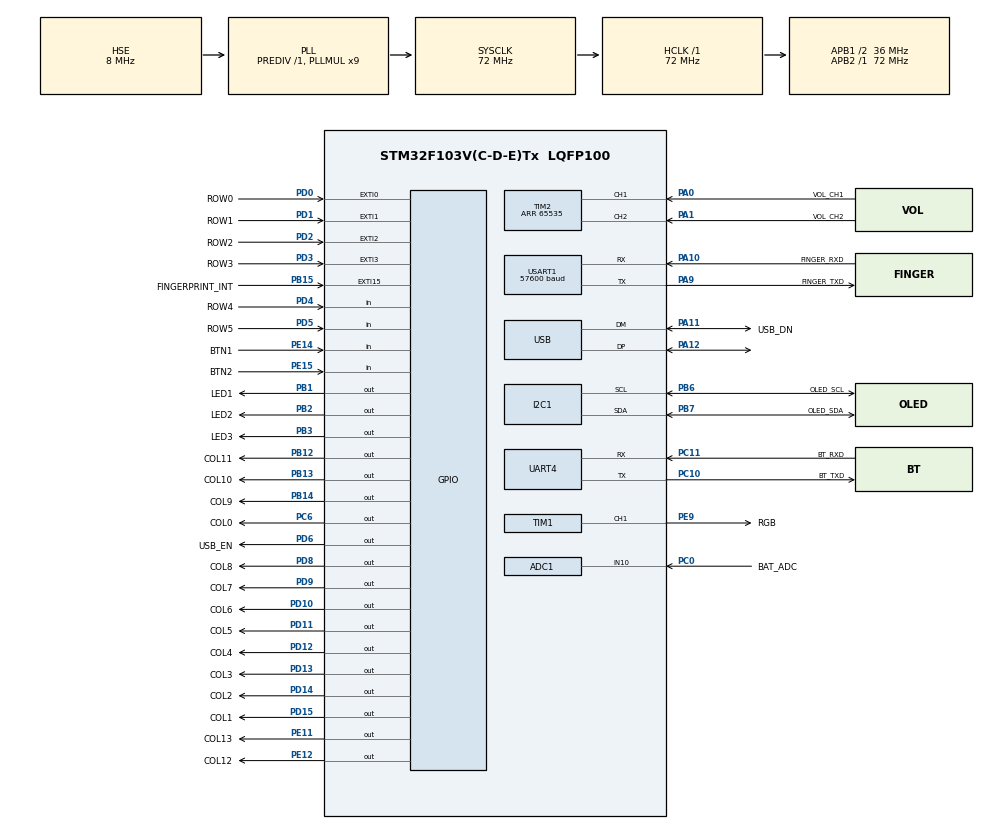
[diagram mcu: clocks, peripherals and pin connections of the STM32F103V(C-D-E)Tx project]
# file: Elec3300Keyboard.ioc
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ADC1.Channel-0\#ChannelRegularConversion=ADC_CHANNEL_10
ADC1.ContinuousConvMode=ENABLE
ADC1.NbrOfConversionFlag=1
ADC1.Rank-0\#ChannelRegularConversion=1
ADC1.SamplingTime-0\#ChannelRegularConversion=ADC_SAMPLETIME_1CYCLE_5
ADC1.master=1
Dma.Request0=TIM1_CH1
Dma.TIM1_CH1.0.Direction=DMA_MEMORY_TO_PERIPH
Dma.TIM1_CH1.0.Instance=DMA1_Channel2
Dma.TIM1_CH1.0.MemDataAlignment=DMA_MDATAALIGN_WORD
Dma.TIM1_CH1.0.MemInc=DMA_MINC_ENABLE
Dma.TIM1_CH1.0.Mode=DMA_NORMAL
Dma.TIM1_CH1.0.PeriphDataAlignment=DMA_PDATAALIGN_HALFWORD
Dma.TIM1_CH1.0.PeriphInc=DMA_PINC_DISABLE
Dma.TIM1_CH1.0.Priority=DMA_PRIORITY_LOW
FREERTOS.HEAP_NUMBER=3
FREERTOS.Tasks01=KeyTask,3,128,StartUSBTask,Default,NULL,Dynamic,NULL,NULL;OLEDTask,-3,128,StartOLEDTask,Default,NULL,Dynamic,NULL,NULL;RGBTask,-3,128,WS2812_LED_Task,Default,NULL,Dynamic,NULL,NULL;debugTask,-3,128,StartDebugTask,Default,NULL,Dynamic,NULL,NULL
Mcu.Family=STM32F1
Mcu.Name=STM32F103V(C-D-E)Tx
Mcu.Package=LQFP100
NVIC.DMA1_Channel2_IRQn=true\:5\:0\:false\:false\:true\:true\:false\:true
NVIC.EXTI0_IRQn=true\:5\:0\:false\:false\:true\:true\:true\:true
NVIC.EXTI15_10_IRQn=true\:5\:0\:false\:false\:true\:true\:true\:true
NVIC.EXTI1_IRQn=true\:5\:0\:false\:false\:true\:true\:true\:true
NVIC.EXTI2_IRQn=true\:5\:0\:false\:false\:true\:true\:true\:true
NVIC.EXTI3_IRQn=true\:5\:0\:false\:false\:true\:true\:true\:true
NVIC.PriorityGroup=NVIC_PRIORITYGROUP_4
NVIC.TIM2_IRQn=true\:5\:0\:false\:false\:true\:true\:true\:true
NVIC.TIM6_IRQn=true\:0\:0\:false\:false\:true\:false\:false\:true
NVIC.TimeBase=TIM6_IRQn
NVIC.TimeBaseIP=TIM6
NVIC.USB_LP_CAN1_RX0_IRQn=true\:5\:0\:false\:false\:true\:true\:false\:true
OSC_IN.Mode=HSE-External-Oscillator
OSC_IN.Signal=RCC_OSC_IN
OSC_OUT.Mode=HSE-External-Oscillator
OSC_OUT.Signal=RCC_OSC_OUT
PA0-WKUP.GPIO_Label=VOL_CH1
PA0-WKUP.GPIO_PuPd=GPIO_PULLUP
PA0-WKUP.Signal=S_TIM2_CH1_ETR
PA1.GPIO_Label=VOL_CH2
PA1.GPIO_PuPd=GPIO_PULLUP
PA1.Signal=S_TIM2_CH2
PA10.GPIO_Label=FINGER_RXD
PA10.Mode=Asynchronous
PA10.Signal=USART1_RX
PA11.GPIO_Label=USB_DN
PA11.Mode=Device
PA11.Signal=USB_DM
PA12.Mode=Device
PA12.Signal=USB_DP
PA13.Mode=Serial_Wire
PA13.Signal=SYS_JTMS-SWDIO
PA14.Mode=Serial_Wire
PA14.Signal=SYS_JTCK-SWCLK
PA9.GPIO_Label=FINGER_TXD
PA9.Mode=Asynchronous
PA9.Signal=USART1_TX
PB1.GPIO_Label=LED1
PB1.Signal=GPIO_Output
PB12.GPIO_Label=COL11
PB12.Signal=GPIO_Output
PB13.GPIO_Label=COL10
PB13.Signal=GPIO_Output
PB14.GPIO_Label=COL9
PB14.Signal=GPIO_Output
PB15.GPIO_Label=FINGERPRINT_INT
PB15.GPIO_PuPd=GPIO_PULLDOWN
PB15.Signal=GPXTI15
PB2.GPIO_Label=LED2
PB2.Signal=GPIO_Output
PB3.GPIO_Label=LED3
PB3.Signal=GPIO_Output
PB6.GPIO_Label=OLED_SCL
PB6.Mode=I2C
PB6.Signal=I2C1_SCL
PB7.GPIO_Label=OLED_SDA
PB7.Mode=I2C
PB7.Signal=I2C1_SDA
PC0.GPIO_Label=BAT_ADC
PC0.Signal=ADCx_IN10
PC10.GPIO_Label=BT_TXD
PC10.Mode=Asynchronous
PC10.Signal=UART4_TX
PC11.GPIO_Label=BT_RXD
PC11.Mode=Asynchronous
PC11.Signal=UART4_RX
PC14-OSC32_IN.Mode=LSE-External-Oscillator
PC14-OSC32_IN.Signal=RCC_OSC32_IN
PC15-OSC32_OUT.Mode=LSE-External-Oscillator
PC15-OSC32_OUT.Signal=RCC_OSC32_OUT
PC6.GPIO_Label=COL0
PC6.Signal=GPIO_Output
PD0.GPIO_Label=ROW0
PD0.GPIO_PuPd=GPIO_PULLDOWN
PD0.Signal=GPXTI0
PD1.GPIO_Label=ROW1
PD1.GPIO_PuPd=GPIO_PULLDOWN
PD1.Signal=GPXTI1
PD10.GPIO_Label=COL6
PD10.Signal=GPIO_Output
PD11.GPIO_Label=COL5
PD11.Signal=GPIO_Output
PD12.GPIO_Label=COL4
PD12.Signal=GPIO_Output
PD13.GPIO_Label=COL3
PD13.Signal=GPIO_Output
PD14.GPIO_Label=COL2
PD14.Signal=GPIO_Output
PD15.GPIO_Label=COL1
PD15.Signal=GPIO_Output
PD2.GPIO_Label=ROW2
PD2.GPIO_PuPd=GPIO_PULLDOWN
PD2.Signal=GPXTI2
PD3.GPIO_Label=ROW3
PD3.GPIO_PuPd=GPIO_PULLDOWN
PD3.Signal=GPXTI3
PD4.GPIO_Label=ROW4
PD4.GPIO_PuPd=GPIO_PULLDOWN
PD4.Signal=GPIO_Input
PD5.GPIO_Label=ROW5
PD5.GPIO_PuPd=GPIO_PULLDOWN
PD5.Signal=GPIO_Input
PD6.GPIO_Label=USB_EN
PD6.Signal=GPIO_Output
PD8.GPIO_Label=COL8
PD8.Signal=GPIO_Output
PD9.GPIO_Label=COL7
PD9.Signal=GPIO_Output
PE11.GPIO_Label=COL13
PE11.Signal=GPIO_Output
PE12.GPIO_Label=COL12
PE12.Signal=GPIO_Output
PE14.GPIO_Label=BTN1
PE14.GPIO_PuPd=GPIO_PULLDOWN
PE14.Signal=GPIO_Input
PE15.GPIO_Label=BTN2
PE15.GPIO_PuPd=GPIO_PULLDOWN
PE15.Signal=GPIO_Input
PE9.GPIO_Label=RGB
PE9.Signal=S_TIM1_CH1
ProjectManager.HeapSize=0x200
ProjectManager.StackSize=0x400
ProjectManager.TargetToolchain=Makefile
RCC.ADCPresc=RCC_ADCPCLK2_DIV6
RCC.AHBFreq_Value=72000000
RCC.APB1CLKDivider=RCC_HCLK_DIV2
RCC.APB1Freq_Value=36000000
RCC.APB1TimFreq_Value=72000000
RCC.APB2Freq_Value=72000000
RCC.APB2TimFreq_Value=72000000
RCC.HCLKFreq_Value=72000000
RCC.PLLMUL=RCC_PLL_MUL9
RCC.SYSCLKFreq_VALUE=72000000
RCC.SYSCLKSource=RCC_SYSCLKSOURCE_PLLCLK
RCC.USBFreq_Value=48000000
RCC.USBPrescaler=RCC_USBCLKSOURCE_PLL_DIV1_5
SH.ADCx_IN10.0=ADC1_IN10,IN10
SH.S_TIM1_CH1.0=TIM1_CH1,PWM Generation1 CH1
SH.S_TIM2_CH1_ETR.0=TIM2_CH1,Encoder_Interface
SH.S_TIM2_CH2.0=TIM2_CH2,Encoder_Interface
TIM1.Channel-PWM\ Generation1\ CH1=TIM_CHANNEL_1
TIM1.Channel-PWM\ Generation2\ CH2=TIM_CHANNEL_2
TIM1.Period=50-1
TIM1.Prescaler=2-1
TIM1.Pulse-PWM\ Generation1\ CH1=0
TIM2.AutoReloadPreload=TIM_AUTORELOAD_PRELOAD_DISABLE
TIM2.EncoderMode=TIM_ENCODERMODE_TI12
TIM2.IC1Polarity=TIM_ICPOLARITY_FALLING
TIM2.IC2Polarity=TIM_ICPOLARITY_FALLING
TIM2.Period=65535
UART4.VirtualMode=Asynchronous
USART1.BaudRate=57600
USART1.VirtualMode=VM_ASYNC
USB_DEVICE.CLASS_NAME_FS=HID
USB_DEVICE.PRODUCT_STRING_HID_FS=STM32keyboard
USB_DEVICE.VirtualMode=Hid
USB_DEVICE.VirtualModeFS=Hid_FS
VP_FREERTOS_VS_CMSIS_V1.Mode=CMSIS_V1
VP_SYS_VS_tim6.Mode=TIM6
VP_TIM1_VS_ClockSourceINT.Mode=Internal
VP_USB_DEVICE_VS_USB_DEVICE_HID_FS.Mode=HID_FS
board=custom

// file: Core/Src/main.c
/* USER CODE BEGIN Header */
/* USER CODE END Header */

#include "main.h"

#include "cmsis_os.h"
#include "usb_device.h"

/* USER CODE BEGIN Includes */
#include "RGB.h"
#include "battery.h"
#include "display_manager.h"
#include "fingerprint.h"
#include "host_OS.h"
#include "key_handler.h"
#include "matrix_button.h"
#include "oled_manager.h"
#include "ssd1306.h"
#include "volume.h"
/* USER CODE END Includes */

ADC_HandleTypeDef hadc1;

I2C_HandleTypeDef hi2c1;

TIM_HandleTypeDef htim1;
TIM_HandleTypeDef htim2;
DMA_HandleTypeDef hdma_tim1_ch1;

UART_HandleTypeDef huart4;
UART_HandleTypeDef huart1;

osThreadId KeyTaskHandle;
osThreadId OLEDTaskHandle;
osThreadId RGBTaskHandle;
osThreadId debugTaskHandle;
/* USER CODE BEGIN PV */
extern WS2812 ws2812;
/* USER CODE END PV */

void SystemClock_Config(void);
static void MX_GPIO_Init(void);
static void MX_ADC1_Init(void);
static void MX_TIM1_Init(void);
static void MX_I2C1_Init(void);
static void MX_DMA_Init(void);
static void MX_UART4_Init(void);
static void MX_TIM2_Init(void);
static void MX_USART1_UART_Init(void);
void StartUSBTask(void const *argument);
void StartOLEDTask(void const *argument);
void WS2812_LED_Task(void const *argument);
void StartDebugTask(void const *argument);

int main(void) {

    /* MCU Configuration--------------------------------------------------------*/

    /* Reset of all peripherals, Initializes the Flash interface and the Systick. */
    HAL_Init();

    /* Configure the system clock */
    SystemClock_Config();

    /* Initialize all configured peripherals */
    MX_GPIO_Init();
    MX_ADC1_Init();
    MX_DMA_Init();
    MX_TIM1_Init();
    MX_I2C1_Init();
    MX_UART4_Init();
    MX_TIM2_Init();
    MX_USART1_UART_Init();
    /* USER CODE BEGIN 2 */
    HAL_ADCEx_Calibration_Start(&hadc1);
    HAL_ADC_Start(&hadc1);
    HAL_TIM_Encoder_Start_IT(&htim2, TIM_CHANNEL_ALL);
    /* USER CODE END 2 */

    /* Create the thread(s) */
    /* definition and creation of KeyTask */
    osThreadDef(KeyTask, StartUSBTask, osPriorityRealtime, 0, 128);
    KeyTaskHandle = osThreadCreate(osThread(KeyTask), NULL);

    /* definition and creation of OLEDTask */
    osThreadDef(OLEDTask, StartOLEDTask, osPriorityIdle, 0, 128);
    OLEDTaskHandle = osThreadCreate(osThread(OLEDTask), NULL);

    /* definition and creation of RGBTask */
    osThreadDef(RGBTask, WS2812_LED_Task, osPriorityIdle, 0, 128);
    RGBTaskHandle = osThreadCreate(osThread(RGBTask), NULL);

    /* definition and creation of debugTask */
    osThreadDef(debugTask, StartDebugTask, osPriorityIdle, 0, 128);
    debugTaskHandle = osThreadCreate(osThread(debugTask), NULL);

    /* Start scheduler */
    osKernelStart();

    /* We should never get here as control is now taken by the scheduler */

    /* Infinite loop */

}

void SystemClock_Config(void) {
    RCC_OscInitTypeDef RCC_OscInitStruct = {0};
    RCC_ClkInitTypeDef RCC_ClkInitStruct = {0};
    RCC_PeriphCLKInitTypeDef PeriphClkInit = {0};

    /** Initializes the CPU, AHB and APB busses clocks
  */
    RCC_OscInitStruct.OscillatorType = RCC_OSCILLATORTYPE_HSE;
    RCC_OscInitStruct.HSEState = RCC_HSE_ON;
    RCC_OscInitStruct.HSEPredivValue = RCC_HSE_PREDIV_DIV1;
    RCC_OscInitStruct.HSIState = RCC_HSI_ON;
    RCC_OscInitStruct.PLL.PLLState = RCC_PLL_ON;
    RCC_OscInitStruct.PLL.PLLSource = RCC_PLLSOURCE_HSE;
    RCC_OscInitStruct.PLL.PLLMUL = RCC_PLL_MUL9;
    if (HAL_RCC_OscConfig(&RCC_OscInitStruct) != HAL_OK) {
        Error_Handler();
    }
    /** Initializes the CPU, AHB and APB busses clocks
  */
    RCC_ClkInitStruct.ClockType = RCC_CLOCKTYPE_HCLK | RCC_CLOCKTYPE_SYSCLK | RCC_CLOCKTYPE_PCLK1 | RCC_CLOCKTYPE_PCLK2;
    RCC_ClkInitStruct.SYSCLKSource = RCC_SYSCLKSOURCE_PLLCLK;
    RCC_ClkInitStruct.AHBCLKDivider = RCC_SYSCLK_DIV1;
    RCC_ClkInitStruct.APB1CLKDivider = RCC_HCLK_DIV2;
    RCC_ClkInitStruct.APB2CLKDivider = RCC_HCLK_DIV1;

    if (HAL_RCC_ClockConfig(&RCC_ClkInitStruct, FLASH_LATENCY_2) != HAL_OK) {
        Error_Handler();
    }
    PeriphClkInit.PeriphClockSelection = RCC_PERIPHCLK_ADC | RCC_PERIPHCLK_USB;
    PeriphClkInit.AdcClockSelection = RCC_ADCPCLK2_DIV6;
    PeriphClkInit.UsbClockSelection = RCC_USBCLKSOURCE_PLL_DIV1_5;
    if (HAL_RCCEx_PeriphCLKConfig(&PeriphClkInit) != HAL_OK) {
        Error_Handler();
    }
}

static void MX_ADC1_Init(void) {

    ADC_ChannelConfTypeDef sConfig = {0};

    /** Common config
  */
    hadc1.Instance = ADC1;
    hadc1.Init.ScanConvMode = ADC_SCAN_DISABLE;
    hadc1.Init.ContinuousConvMode = ENABLE;
    hadc1.Init.DiscontinuousConvMode = DISABLE;
    hadc1.Init.ExternalTrigConv = ADC_SOFTWARE_START;
    hadc1.Init.DataAlign = ADC_DATAALIGN_RIGHT;
    hadc1.Init.NbrOfConversion = 1;
    if (HAL_ADC_Init(&hadc1) != HAL_OK) {
        Error_Handler();
    }
    /** Configure Regular Channel
  */
    sConfig.Channel = ADC_CHANNEL_10;
    sConfig.Rank = ADC_REGULAR_RANK_1;
    sConfig.SamplingTime = ADC_SAMPLETIME_1CYCLE_5;
    if (HAL_ADC_ConfigChannel(&hadc1, &sConfig) != HAL_OK) {
        Error_Handler();
    }
}

static void MX_I2C1_Init(void) {

    hi2c1.Instance = I2C1;
    hi2c1.Init.ClockSpeed = 100000;
    hi2c1.Init.DutyCycle = I2C_DUTYCYCLE_2;
    hi2c1.Init.OwnAddress1 = 0;
    hi2c1.Init.AddressingMode = I2C_ADDRESSINGMODE_7BIT;
    hi2c1.Init.DualAddressMode = I2C_DUALADDRESS_DISABLE;
    hi2c1.Init.OwnAddress2 = 0;
    hi2c1.Init.GeneralCallMode = I2C_GENERALCALL_DISABLE;
    hi2c1.Init.NoStretchMode = I2C_NOSTRETCH_DISABLE;
    if (HAL_I2C_Init(&hi2c1) != HAL_OK) {
        Error_Handler();
    }
}

static void MX_TIM1_Init(void) {

    TIM_ClockConfigTypeDef sClockSourceConfig = {0};
    TIM_MasterConfigTypeDef sMasterConfig = {0};
    TIM_OC_InitTypeDef sConfigOC = {0};
    TIM_BreakDeadTimeConfigTypeDef sBreakDeadTimeConfig = {0};

    htim1.Instance = TIM1;
    htim1.Init.Prescaler = 2 - 1;
    htim1.Init.CounterMode = TIM_COUNTERMODE_UP;
    htim1.Init.Period = 50 - 1;
    htim1.Init.ClockDivision = TIM_CLOCKDIVISION_DIV1;
    htim1.Init.RepetitionCounter = 0;
    htim1.Init.AutoReloadPreload = TIM_AUTORELOAD_PRELOAD_DISABLE;
    if (HAL_TIM_Base_Init(&htim1) != HAL_OK) {
        Error_Handler();
    }
    sClockSourceConfig.ClockSource = TIM_CLOCKSOURCE_INTERNAL;
    if (HAL_TIM_ConfigClockSource(&htim1, &sClockSourceConfig) != HAL_OK) {
        Error_Handler();
    }
    if (HAL_TIM_PWM_Init(&htim1) != HAL_OK) {
        Error_Handler();
    }
    sMasterConfig.MasterOutputTrigger = TIM_TRGO_RESET;
    sMasterConfig.MasterSlaveMode = TIM_MASTERSLAVEMODE_DISABLE;
    if (HAL_TIMEx_MasterConfigSynchronization(&htim1, &sMasterConfig) != HAL_OK) {
        Error_Handler();
    }
    sConfigOC.OCMode = TIM_OCMODE_PWM1;
    sConfigOC.Pulse = 0;
    sConfigOC.OCPolarity = TIM_OCPOLARITY_HIGH;
    sConfigOC.OCNPolarity = TIM_OCNPOLARITY_HIGH;
    sConfigOC.OCFastMode = TIM_OCFAST_DISABLE;
    sConfigOC.OCIdleState = TIM_OCIDLESTATE_RESET;
    sConfigOC.OCNIdleState = TIM_OCNIDLESTATE_RESET;
    if (HAL_TIM_PWM_ConfigChannel(&htim1, &sConfigOC, TIM_CHANNEL_1) != HAL_OK) {
        Error_Handler();
    }
    sBreakDeadTimeConfig.OffStateRunMode = TIM_OSSR_DISABLE;
    sBreakDeadTimeConfig.OffStateIDLEMode = TIM_OSSI_DISABLE;
    sBreakDeadTimeConfig.LockLevel = TIM_LOCKLEVEL_OFF;
    sBreakDeadTimeConfig.DeadTime = 0;
    sBreakDeadTimeConfig.BreakState = TIM_BREAK_DISABLE;
    sBreakDeadTimeConfig.BreakPolarity = TIM_BREAKPOLARITY_HIGH;
    sBreakDeadTimeConfig.AutomaticOutput = TIM_AUTOMATICOUTPUT_DISABLE;
    if (HAL_TIMEx_ConfigBreakDeadTime(&htim1, &sBreakDeadTimeConfig) != HAL_OK) {
        Error_Handler();
    }
    HAL_TIM_MspPostInit(&htim1);
}

static void MX_TIM2_Init(void) {

    TIM_Encoder_InitTypeDef sConfig = {0};
    TIM_MasterConfigTypeDef sMasterConfig = {0};

    htim2.Instance = TIM2;
    htim2.Init.Prescaler = 0;
    htim2.Init.CounterMode = TIM_COUNTERMODE_UP;
    htim2.Init.Period = 65535;
    htim2.Init.ClockDivision = TIM_CLOCKDIVISION_DIV1;
    htim2.Init.AutoReloadPreload = TIM_AUTORELOAD_PRELOAD_DISABLE;
    sConfig.EncoderMode = TIM_ENCODERMODE_TI12;
    sConfig.IC1Polarity = TIM_ICPOLARITY_FALLING;
    sConfig.IC1Selection = TIM_ICSELECTION_DIRECTTI;
    sConfig.IC1Prescaler = TIM_ICPSC_DIV1;
    sConfig.IC1Filter = 0;
    sConfig.IC2Polarity = TIM_ICPOLARITY_FALLING;
    sConfig.IC2Selection = TIM_ICSELECTION_DIRECTTI;
    sConfig.IC2Prescaler = TIM_ICPSC_DIV1;
    sConfig.IC2Filter = 0;
    if (HAL_TIM_Encoder_Init(&htim2, &sConfig) != HAL_OK) {
        Error_Handler();
    }
    sMasterConfig.MasterOutputTrigger = TIM_TRGO_RESET;
    sMasterConfig.MasterSlaveMode = TIM_MASTERSLAVEMODE_DISABLE;
    if (HAL_TIMEx_MasterConfigSynchronization(&htim2, &sMasterConfig) != HAL_OK) {
        Error_Handler();
    }
}

static void MX_UART4_Init(void) {

    huart4.Instance = UART4;
    huart4.Init.BaudRate = 115200;
    huart4.Init.WordLength = UART_WORDLENGTH_8B;
    huart4.Init.StopBits = UART_STOPBITS_1;
    huart4.Init.Parity = UART_PARITY_NONE;
    huart4.Init.Mode = UART_MODE_TX_RX;
    huart4.Init.HwFlowCtl = UART_HWCONTROL_NONE;
    huart4.Init.OverSampling = UART_OVERSAMPLING_16;
    if (HAL_UART_Init(&huart4) != HAL_OK) {
        Error_Handler();
    }
}

static void MX_USART1_UART_Init(void) {

    huart1.Instance = USART1;
    huart1.Init.BaudRate = 57600;
    huart1.Init.WordLength = UART_WORDLENGTH_8B;
    huart1.Init.StopBits = UART_STOPBITS_1;
    huart1.Init.Parity = UART_PARITY_NONE;
    huart1.Init.Mode = UART_MODE_TX_RX;
    huart1.Init.HwFlowCtl = UART_HWCONTROL_NONE;
    huart1.Init.OverSampling = UART_OVERSAMPLING_16;
    if (HAL_UART_Init(&huart1) != HAL_OK) {
        Error_Handler();
    }
}

static void MX_DMA_Init(void) {
    /* DMA controller clock enable */
    __HAL_RCC_DMA1_CLK_ENABLE();

    /* DMA interrupt init */
    /* DMA1_Channel2_IRQn interrupt configuration */
    HAL_NVIC_SetPriority(DMA1_Channel2_IRQn, 5, 0);
    HAL_NVIC_EnableIRQ(DMA1_Channel2_IRQn);
}

static void MX_GPIO_Init(void) {
    GPIO_InitTypeDef GPIO_InitStruct = {0};

    /* GPIO Ports Clock Enable */
    __HAL_RCC_GPIOC_CLK_ENABLE();
    __HAL_RCC_GPIOA_CLK_ENABLE();
    __HAL_RCC_GPIOB_CLK_ENABLE();
    __HAL_RCC_GPIOE_CLK_ENABLE();
    __HAL_RCC_GPIOD_CLK_ENABLE();

    /*Configure GPIO pin Output Level */
    HAL_GPIO_WritePin(GPIOB, LED1_Pin | LED2_Pin | COL11_Pin | COL10_Pin | COL9_Pin | LED3_Pin, GPIO_PIN_RESET);

    /*Configure GPIO pin Output Level */
    HAL_GPIO_WritePin(GPIOE, COL13_Pin | COL12_Pin, GPIO_PIN_RESET);

    /*Configure GPIO pin Output Level */
    HAL_GPIO_WritePin(GPIOD, COL8_Pin | COL7_Pin | COL6_Pin | COL5_Pin | COL4_Pin | COL3_Pin | COL2_Pin | COL1_Pin | USB_EN_Pin, GPIO_PIN_RESET);

    /*Configure GPIO pin Output Level */
    HAL_GPIO_WritePin(COL0_GPIO_Port, COL0_Pin, GPIO_PIN_RESET);

    /*Configure GPIO pins : LED1_Pin LED2_Pin COL11_Pin COL10_Pin
                           COL9_Pin LED3_Pin */
    GPIO_InitStruct.Pin = LED1_Pin | LED2_Pin | COL11_Pin | COL10_Pin | COL9_Pin | LED3_Pin;
    GPIO_InitStruct.Mode = GPIO_MODE_OUTPUT_PP;
    GPIO_InitStruct.Pull = GPIO_NOPULL;
    GPIO_InitStruct.Speed = GPIO_SPEED_FREQ_LOW;
    HAL_GPIO_Init(GPIOB, &GPIO_InitStruct);

    /*Configure GPIO pins : COL13_Pin COL12_Pin */
    GPIO_InitStruct.Pin = COL13_Pin | COL12_Pin;
    GPIO_InitStruct.Mode = GPIO_MODE_OUTPUT_PP;
    GPIO_InitStruct.Pull = GPIO_NOPULL;
    GPIO_InitStruct.Speed = GPIO_SPEED_FREQ_LOW;
    HAL_GPIO_Init(GPIOE, &GPIO_InitStruct);

    /*Configure GPIO pins : BTN1_Pin BTN2_Pin */
    GPIO_InitStruct.Pin = BTN1_Pin | BTN2_Pin;
    GPIO_InitStruct.Mode = GPIO_MODE_INPUT;
    GPIO_InitStruct.Pull = GPIO_PULLDOWN;
    HAL_GPIO_Init(GPIOE, &GPIO_InitStruct);

    /*Configure GPIO pin : FINGERPRINT_INT_Pin */
    GPIO_InitStruct.Pin = FINGERPRINT_INT_Pin;
    GPIO_InitStruct.Mode = GPIO_MODE_IT_RISING;
    GPIO_InitStruct.Pull = GPIO_PULLDOWN;
    HAL_GPIO_Init(FINGERPRINT_INT_GPIO_Port, &GPIO_InitStruct);

    /*Configure GPIO pins : COL8_Pin COL7_Pin COL6_Pin COL5_Pin
                           COL4_Pin COL3_Pin COL2_Pin COL1_Pin
                           USB_EN_Pin */
    GPIO_InitStruct.Pin = COL8_Pin | COL7_Pin | COL6_Pin | COL5_Pin | COL4_Pin | COL3_Pin | COL2_Pin | COL1_Pin | USB_EN_Pin;
    GPIO_InitStruct.Mode = GPIO_MODE_OUTPUT_PP;
    GPIO_InitStruct.Pull = GPIO_NOPULL;
    GPIO_InitStruct.Speed = GPIO_SPEED_FREQ_LOW;
    HAL_GPIO_Init(GPIOD, &GPIO_InitStruct);

    /*Configure GPIO pin : ENC_SW_Pin */
    GPIO_InitStruct.Pin = ENC_SW_Pin;
    GPIO_InitStruct.Mode = GPIO_MODE_INPUT;
    GPIO_InitStruct.Pull = GPIO_PULLUP;
    HAL_GPIO_Init(ENC_SW_GPIO_Port, &GPIO_InitStruct);

    /*Configure GPIO pin : COL0_Pin */
    GPIO_InitStruct.Pin = COL0_Pin;
    GPIO_InitStruct.Mode = GPIO_MODE_OUTPUT_PP;
    GPIO_InitStruct.Pull = GPIO_NOPULL;
    GPIO_InitStruct.Speed = GPIO_SPEED_FREQ_LOW;
    HAL_GPIO_Init(COL0_GPIO_Port, &GPIO_InitStruct);

    /*Configure GPIO pins : ROW0_Pin ROW1_Pin ROW2_Pin ROW3_Pin */
    GPIO_InitStruct.Pin = ROW0_Pin | ROW1_Pin | ROW2_Pin | ROW3_Pin;
    GPIO_InitStruct.Mode = GPIO_MODE_IT_RISING;
    GPIO_InitStruct.Pull = GPIO_PULLDOWN;
    HAL_GPIO_Init(GPIOD, &GPIO_InitStruct);

    /*Configure GPIO pins : ROW4_Pin ROW5_Pin */
    GPIO_InitStruct.Pin = ROW4_Pin | ROW5_Pin;
    GPIO_InitStruct.Mode = GPIO_MODE_INPUT;
    GPIO_InitStruct.Pull = GPIO_PULLDOWN;
    HAL_GPIO_Init(GPIOD, &GPIO_InitStruct);

    /* EXTI interrupt init*/
    HAL_NVIC_SetPriority(EXTI0_IRQn, 5, 0);
    HAL_NVIC_EnableIRQ(EXTI0_IRQn);

    HAL_NVIC_SetPriority(EXTI1_IRQn, 5, 0);
    HAL_NVIC_EnableIRQ(EXTI1_IRQn);

    HAL_NVIC_SetPriority(EXTI2_IRQn, 5, 0);
    HAL_NVIC_EnableIRQ(EXTI2_IRQn);

    HAL_NVIC_SetPriority(EXTI3_IRQn, 5, 0);
    HAL_NVIC_EnableIRQ(EXTI3_IRQn);

    HAL_NVIC_SetPriority(EXTI15_10_IRQn, 5, 0);
    HAL_NVIC_EnableIRQ(EXTI15_10_IRQn);
}

void StartUSBTask(void const *argument) {
    /* init code for USB_DEVICE */
    MX_USB_DEVICE_Init();

    /* USER CODE BEGIN 5 */
    /* Infinite loop */
    HAL_GPIO_WritePin(USB_EN_GPIO_Port, USB_EN_Pin, 0);

    key_thread();
    /* USER CODE END 5 */
}

/* USER CODE BEGIN Header_StartOLEDTask */
uint32_t last_keyinterrupt_tick = 0;
uint32_t SLEEPMODE_TIMEOUT = 10000;
uint8_t ssd_do_once_flag = 1;
uint8_t sleep_mode = 0;
extern KEYBOARD_OPERATION_MODE keyboard_operation_mode;
uint32_t oled_tick = 0;
uint8_t send_password_flag = 0;

void HAL_GPIO_EXTI_Callback(uint16_t GPIO_Pin) {
    // if (GPIO_Pin == ROW0_Pin || GPIO_Pin == ROW1_Pin || GPIO_Pin == ROW2_Pin ||
    //     GPIO_Pin == ROW3_Pin) {
    //     last_keyinterrupt_tick = HAL_GetTick();
    //     sleep_mode = 0;
    //     ssd_do_once_flag = 1;
    // }
    // if (GPIO_Pin == FINGERPRINT_INT_Pin) {
    //     if (keyboard_operation_mode == KEYBOARD_OPERATION_MODE_NORMAL) {
    //         uint8_t result = check_fingerprint();
    //         if (result == 0) {
    //             led_mode(0);
    //             send_password_flag = 1;
    //             led_mode(1);
    //         }
    //     }
    // }
}
/**
* @brief Function implementing the OLEDTask thread.
* @param argument: Not used
* @retval None
*/
/* USER CODE END Header_StartOLEDTask */
void StartOLEDTask(void const *argument) {
    /* USER CODE BEGIN StartOLEDTask */
    ssd1306_Init();
    display_manager_init();
    for (;;) {
        // ssd1306_WriteChar('A', Font_16x26, 0x01);
        // if (send_password_flag) {
        //     send_password();
        //     send_password_flag = 0;
        // }
        // if (HAL_GetTick() - last_keyinterrupt_tick > SLEEPMODE_TIMEOUT) {
        //     sleep_mode = 1;
        // }

        // if (sleep_mode)
        //     ssd1306_SetDisplayOn(0);
        // else {
        //     if (ssd_do_once_flag) {
        //         ssd1306_SetDisplayOn(1);
        //         ssd_do_once_flag = 0;
        //     }
        //     if (HAL_GetTick() - oled_tick > 1000 &&
        //         keyboard_operation_mode == KEYBOARD_OPERATION_MODE_NORMAL) {
        //         oled_update_page();
        //         oled_tick = HAL_GetTick();
        //     }
        // }
        // if (button_read(&b))
        //     b.button_clicked_listener(&b, BUTTON_CLICKED);
        // else
        //     b.button_released_listener(&b, BUTTON_RELEASED);
        // ssd1306_WriteString("Hello", Font_6x8, 0x01);
        display_manager_update();
        osDelay(100);
    }
    /* USER CODE END StartOLEDTask */
}

/* USER CODE BEGIN Header_WS2812_LED_Task */
/**
* @brief Function implementing the RGBTask thread.
* @param argument: Not used
* @retval None
*/
extern uint32_t brightness;  // range from 0(nolight) to 99(full)
extern uint8_t speed;        // range from 0(slowest) to 99(fastest)
extern WS2812Mode rgb_mode;
/* USER CODE END Header_WS2812_LED_Task */
void WS2812_LED_Task(void const *argument) {
    /* USER CODE BEGIN WS2812_LED_Task */
    WS2812_InitStruct ws2812_initStruct = {.LED_num = MAX_LED, .tim = &htim1, .channel = TIM_CHANNEL_1};
    WS2812_init(&ws2812, &ws2812_initStruct);

    for (;;) {
        // if (sleep_mode) {
        //     rgb_mode = WS2812DISABLE;
        // }
        WS2812_LED_SetBrightness(&ws2812, brightness);
        switch (rgb_mode) {
        case LOOPMODE:
            WS2812_Loop_Pattern(&ws2812);
            break;
        case BREATHMODE:
            WS2812_Breath_Pattern(&ws2812);
            break;
        case STATICMODE:
            WS2812_Static_Pattern(&ws2812);
            break;
        case LAYEREDMODE:
            WS2812_Layered_Pattern(&ws2812);
            break;
        case STATICBREATHMODE:
            WS2812_Monotonic_Breate_Pattern(&ws2812);
            break;
        case THEMATRIXMODE:
            WS2812_The_Matrix_Hor_Pattern(&ws2812);
            break;
        case WS2812DISABLE:
        default:
            WS2812_TurnOff_Pattern(&ws2812);
            break;
        }
        WS2812_sendData(&ws2812);
        speed = constrain(speed, 0, 99);
        osDelay(200 * (1 - speed / 100.0));
    }
    WS2812_Deinit(&ws2812);
    /* USER CODE END WS2812_LED_Task */
}

void StartDebugTask(void const *argument) {
    /* USER CODE BEGIN StartDebugTask */
    /* Infinite loop */
    for (;;) {
        HAL_GPIO_WritePin(LED2_GPIO_Port, LED2_Pin, 0);
        osDelay(100);
        HAL_GPIO_WritePin(LED2_GPIO_Port, LED2_Pin, 1);
        osDelay(100);

        if(HAL_GPIO_ReadPin(ENC_SW_GPIO_Port, ENC_SW_Pin))
            HAL_GPIO_WritePin(LED1_GPIO_Port, LED1_Pin, 0);
        else
            HAL_GPIO_WritePin(LED1_GPIO_Port, LED1_Pin, 1);
    }
    /* USER CODE END StartDebugTask */
}

void HAL_TIM_PeriodElapsedCallback(TIM_HandleTypeDef *htim) {
    if (htim->Instance == TIM6) {
        HAL_IncTick();
    }
}

void Error_Handler(void) {
}

/************************ (C) COPYRIGHT STMicroelectronics *****END OF FILE****/
